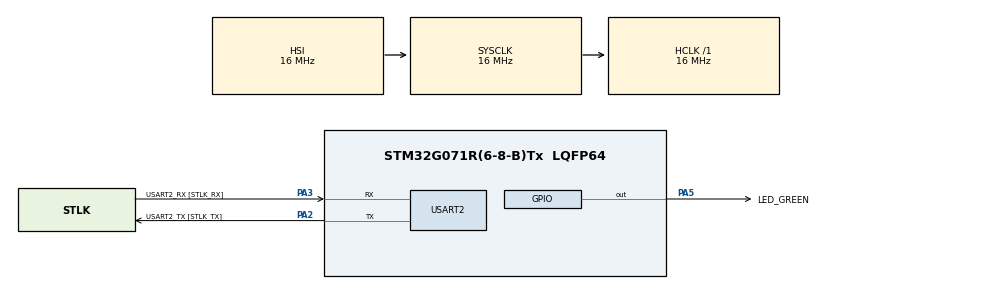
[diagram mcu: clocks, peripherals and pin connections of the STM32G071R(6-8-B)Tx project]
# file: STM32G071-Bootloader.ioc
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Mcu.Family=STM32G0
Mcu.Name=STM32G071R(6-8-B)Tx
Mcu.Package=LQFP64
PA13.GPIO_Label=TMS
PA13.Mode=Serial_Wire
PA13.Signal=SYS_SWDIO
PA14-BOOT0.GPIO_Label=TCK
PA14-BOOT0.Mode=Serial_Wire
PA14-BOOT0.Signal=SYS_SWCLK
PA2.GPIO_Label=USART2_TX [STLK_TX]
PA2.GPIO_PuPd=GPIO_PULLUP
PA2.Mode=Asynchronous
PA2.Signal=USART2_TX
PA3.GPIO_Label=USART2_RX [STLK_RX]
PA3.GPIO_PuPd=GPIO_PULLUP
PA3.Mode=Asynchronous
PA3.Signal=USART2_RX
PA5.GPIO_Label=LED_GREEN
PA5.GPIO_Speed=GPIO_SPEED_FREQ_HIGH
PA5.Signal=GPIO_Output
PC13.Mode=SYS_WakeUp1
PC13.Signal=SYS_WKUP2
PC14-OSC32_IN\ (PC14).Mode=LSE-External-Oscillator
PC14-OSC32_IN\ (PC14).Signal=RCC_OSC32_IN
PC15-OSC32_OUT\ (PC15).Mode=LSE-External-Oscillator
PC15-OSC32_OUT\ (PC15).Signal=RCC_OSC32_OUT
PF0-OSC_IN\ (PF0).GPIO_Label=MCO
PF0-OSC_IN\ (PF0).Mode=HSE-External-Clock-Source
PF0-OSC_IN\ (PF0).Signal=RCC_OSC_IN
ProjectManager.HeapSize=0x200
ProjectManager.StackSize=0x400
ProjectManager.TargetToolchain=STM32CubeIDE
RCC.AHBFreq_Value=16000000
RCC.CortexFreq_Value=16000000
RCC.EXTERNAL_CLOCK_VALUE=12288000
RCC.HCLKFreq_Value=16000000
RCC.HSE_VALUE=8000000
RCC.HSI_VALUE=16000000
RCC.SYSCLKFreq_VALUE=16000000
RCC.VCOOutputFreq_Value=128000000
USART2.VirtualMode-Asynchronous=VM_ASYNC
VP_SYS_VS_DBSignals.Mode=DisableDeadBatterySignals
board=NUCLEO-G071RB

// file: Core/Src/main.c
/* USER CODE BEGIN Header */
/**
  ******************************************************************************
  * @file           : main.c
  * @brief          : Main program body
  ******************************************************************************
  * @attention
  *
  * <h2><center>&copy; Copyright (c) 2022 STMicroelectronics.
  * All rights reserved.</center></h2>
  *
  * This software component is licensed by ST under BSD 3-Clause license,
  * the "License"; You may not use this file except in compliance with the
  * License. You may obtain a copy of the License at:
  *                        opensource.org/licenses/BSD-3-Clause
  *
  ******************************************************************************
  */
/* USER CODE END Header */
#include "main.h"

/* USER CODE BEGIN Includes */
#include <stdio.h>
/* USER CODE END Includes */

/* USER CODE BEGIN PM */

/* Below defines a function pointer called ptrF, with return type void,
 * and a argument of uint32_t.
 */
typedef void (*ptrF)(uint32_t dlyticks);

typedef void (*pFunction)(void);

/* USER CODE END PM */

UART_HandleTypeDef huart2;

/* USER CODE BEGIN PV */

#ifdef FIRST_VIDEO
unsigned char __attribute__((section(".myBufSectionRAM"))) buf_ram[512];

/* If you want to see below 10 pre-set data, you need to :
 * 1. Go to Run -> Debug, press F11;
 * 2. Keep everything default and click OK;
 * 3. Go to Window -> Show View -> Memory -> Click the + Button at Monitors window -> Fill in 0x8001000, which
 *    is the assigned address in linker file.
 */
const unsigned char __attribute__((section(".myBufSectionFLASH"))) buf_flash[10] = {0, 1, 2, 3, 4, 5, 6, 7, 8, 9};
#endif

/* For functions in flash*/
#define LOCATE_FUNC __attribute__((section(".mysection")))

/* We just divided flash into 3 region:
 * (1) FLASH :     0x8000000 - 0x8008000,   LENGTH = 32K
 * (2) TBD
 * (3) MY_MEMORY : 0x8018000 - 0x8020000,   LENGTH = 32K */

/* 0x8000 = 32k Offset (of Flash), the 2nd region in memory define for APP. */
#define FLASH_APP_ADDR 0x8008000

void go2APP(void);

/* USER CODE END PV */

void SystemClock_Config(void);
static void MX_GPIO_Init(void);
static void MX_USART2_UART_Init(void);
/* USER CODE BEGIN PFP */
void LOCATE_FUNC Blink(uint32_t dlyticks);

#ifdef FIRST_VIDEO
static ptrF Functions[] =
{
    Blink
};
#endif

/* USER CODE END PFP */

/* USER CODE BEGIN 0 */

/* Function in Flash */
void LOCATE_FUNC Blink(uint32_t dlyticks)
{
    HAL_GPIO_TogglePin(LED_GREEN_GPIO_Port, LED_GREEN_Pin);
    HAL_Delay(dlyticks);
}

// Before jumping to app, we should disable all IRQs and clear pending IRQs.
// Print content at (FLASH_APP_ADDR) and (FLASH_APP_ADDR + 4).
void go2APP(void)
{
	uint32_t JumpAddress;
	pFunction Jump_To_Application;

	printf("BOOTLOADER Start \r\n");

	// Check if there is something installed in the 'App' region in flash.
	if (((*(uint32_t *)FLASH_APP_ADDR) & 0x2FFE0000) == 0x20000000)
	{
		printf("App Start \r\n");
		HAL_Delay(100);

		// Get data in second 32-bit in app section. First executable address.
		JumpAddress = *(uint32_t *)(FLASH_APP_ADDR + 4);
		Jump_To_Application = (pFunction)JumpAddress;

		// Initialize app's stack pointer
		__set_MSP(*(uint32_t *)FLASH_APP_ADDR);
		Jump_To_Application();
	}
	else
	{
		printf("No App Found \r\n");
		// HAL_Delay(1000);
	}
}
// Below id for using printf() embedded in CubeIDE serial terminal.
int _write(int file, char *ptr, int len)
{
    int DataIdx;

    for (DataIdx = 0; DataIdx < len; DataIdx++)
    {
    	HAL_UART_Transmit(&huart2, (uint8_t *)ptr++, 1, 10);
    }

    return len;
}

/* Function resides in flash, but will load to RAM during initialization. */
// void __attribute__((section(".RamFunc"))) TurnOnLED(GPIO_PinState PinState)
// The __ before and after 'section' doesn't matter.
void __attribute__((__section__(".RamFunc"))) TurnOnLED(GPIO_PinState PinState)
{
	if (PinState != GPIO_PIN_RESET)
	{
		LED_GREEN_GPIO_Port->BSRR = (uint32_t)LED_GREEN_Pin;
	}
	else
	{
		LED_GREEN_GPIO_Port->BRR = (uint32_t)LED_GREEN_Pin;
	}
}

/* USER CODE END 0 */

int main(void)
{

  /* MCU Configuration--------------------------------------------------------*/

  /* Reset of all peripherals, Initializes the Flash interface and the Systick. */
  HAL_Init();

  /* Configure the system clock */
  SystemClock_Config();

  /* Initialize all configured peripherals */
  MX_GPIO_Init();
  MX_USART2_UART_Init();

  /* Infinite loop */
  while (1)
  {

    /* USER CODE BEGIN 3 */
	  // Blink(500);
#ifdef FIRST_VIDEO
	  (*Functions[0])(500);
#endif
	  go2APP();
	  TurnOnLED(GPIO_PIN_SET);
  }
  /* USER CODE END 3 */
}

void SystemClock_Config(void)
{
  RCC_OscInitTypeDef RCC_OscInitStruct = {0};
  RCC_ClkInitTypeDef RCC_ClkInitStruct = {0};
  RCC_PeriphCLKInitTypeDef PeriphClkInit = {0};

  /** Configure the main internal regulator output voltage
  */
  HAL_PWREx_ControlVoltageScaling(PWR_REGULATOR_VOLTAGE_SCALE1);
  /** Initializes the RCC Oscillators according to the specified parameters
  * in the RCC_OscInitTypeDef structure.
  */
  RCC_OscInitStruct.OscillatorType = RCC_OSCILLATORTYPE_HSI;
  RCC_OscInitStruct.HSIState = RCC_HSI_ON;
  RCC_OscInitStruct.HSIDiv = RCC_HSI_DIV1;
  RCC_OscInitStruct.HSICalibrationValue = RCC_HSICALIBRATION_DEFAULT;
  RCC_OscInitStruct.PLL.PLLState = RCC_PLL_NONE;
  if (HAL_RCC_OscConfig(&RCC_OscInitStruct) != HAL_OK)
  {
    Error_Handler();
  }
  /** Initializes the CPU, AHB and APB buses clocks
  */
  RCC_ClkInitStruct.ClockType = RCC_CLOCKTYPE_HCLK|RCC_CLOCKTYPE_SYSCLK
                              |RCC_CLOCKTYPE_PCLK1;
  RCC_ClkInitStruct.SYSCLKSource = RCC_SYSCLKSOURCE_HSI;
  RCC_ClkInitStruct.AHBCLKDivider = RCC_SYSCLK_DIV1;
  RCC_ClkInitStruct.APB1CLKDivider = RCC_HCLK_DIV1;

  if (HAL_RCC_ClockConfig(&RCC_ClkInitStruct, FLASH_LATENCY_0) != HAL_OK)
  {
    Error_Handler();
  }
  /** Initializes the peripherals clocks
  */
  PeriphClkInit.PeriphClockSelection = RCC_PERIPHCLK_USART2;
  PeriphClkInit.Usart2ClockSelection = RCC_USART2CLKSOURCE_PCLK1;
  if (HAL_RCCEx_PeriphCLKConfig(&PeriphClkInit) != HAL_OK)
  {
    Error_Handler();
  }
}

static void MX_USART2_UART_Init(void)
{

  huart2.Instance = USART2;
  huart2.Init.BaudRate = 115200;
  huart2.Init.WordLength = UART_WORDLENGTH_8B;
  huart2.Init.StopBits = UART_STOPBITS_1;
  huart2.Init.Parity = UART_PARITY_NONE;
  huart2.Init.Mode = UART_MODE_TX_RX;
  huart2.Init.HwFlowCtl = UART_HWCONTROL_NONE;
  huart2.Init.OverSampling = UART_OVERSAMPLING_16;
  huart2.Init.OneBitSampling = UART_ONE_BIT_SAMPLE_DISABLE;
  huart2.Init.ClockPrescaler = UART_PRESCALER_DIV1;
  huart2.AdvancedInit.AdvFeatureInit = UART_ADVFEATURE_NO_INIT;
  if (HAL_UART_Init(&huart2) != HAL_OK)
  {
    Error_Handler();
  }
  if (HAL_UARTEx_SetTxFifoThreshold(&huart2, UART_TXFIFO_THRESHOLD_1_8) != HAL_OK)
  {
    Error_Handler();
  }
  if (HAL_UARTEx_SetRxFifoThreshold(&huart2, UART_RXFIFO_THRESHOLD_1_8) != HAL_OK)
  {
    Error_Handler();
  }
  if (HAL_UARTEx_DisableFifoMode(&huart2) != HAL_OK)
  {
    Error_Handler();
  }

}

static void MX_GPIO_Init(void)
{
  GPIO_InitTypeDef GPIO_InitStruct = {0};

  /* GPIO Ports Clock Enable */
  __HAL_RCC_GPIOC_CLK_ENABLE();
  __HAL_RCC_GPIOF_CLK_ENABLE();
  __HAL_RCC_GPIOA_CLK_ENABLE();

  /*Configure GPIO pin Output Level */
  HAL_GPIO_WritePin(LED_GREEN_GPIO_Port, LED_GREEN_Pin, GPIO_PIN_RESET);

  /*Configure GPIO pin : LED_GREEN_Pin */
  GPIO_InitStruct.Pin = LED_GREEN_Pin;
  GPIO_InitStruct.Mode = GPIO_MODE_OUTPUT_PP;
  GPIO_InitStruct.Pull = GPIO_NOPULL;
  GPIO_InitStruct.Speed = GPIO_SPEED_FREQ_HIGH;
  HAL_GPIO_Init(LED_GREEN_GPIO_Port, &GPIO_InitStruct);

}

void Error_Handler(void)
{
  __disable_irq();
  while (1)
  {
  }
}

/************************ (C) COPYRIGHT STMicroelectronics *****END OF FILE****/
